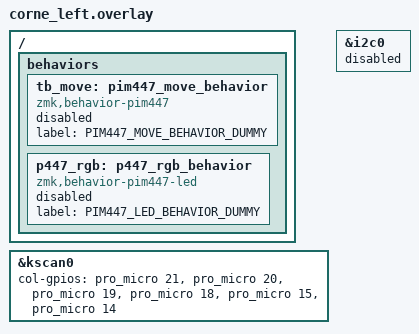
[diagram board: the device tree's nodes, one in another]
/*
 * Copyright (c) 2020 Pete Johanson
 *
 * SPDX-License-Identifier: MIT
 */

#include "corne.dtsi"
#include <dt-bindings/behavior_pim447.h>

&kscan0 {
	col-gpios
		= <&pro_micro 21 GPIO_ACTIVE_HIGH>
		, <&pro_micro 20 GPIO_ACTIVE_HIGH>
		, <&pro_micro 19 GPIO_ACTIVE_HIGH>
		, <&pro_micro 18 GPIO_ACTIVE_HIGH>
		, <&pro_micro 15 GPIO_ACTIVE_HIGH>
		, <&pro_micro 14 GPIO_ACTIVE_HIGH>
		;
};

// 최상위 노드에서 동작을 정의합니다.
/ {
    behaviors {
        // 오른쪽 오버레이와 동일한 라벨을 사용합니다.
        tb_move: pim447_move_behavior {
            compatible = "zmk,behavior-pim447";
            label = "PIM447_MOVE_BEHAVIOR_DUMMY";
            #binding-cells = <1>;
            status = "disabled"; // 핵심: 이 동작은 비활성화합니다.
        };

        p447_rgb: p447_rgb_behavior {
            compatible = "zmk,behavior-pim447-led";
            label = "PIM447_LED_BEHAVIOR_DUMMY";
            #binding-cells = <1>;
            status = "disabled";
        };
    };
};

// I2C0 하드웨어 자체는 비활성화하여 충돌을 막습니다.
&i2c0 {
    status = "disabled";
};
